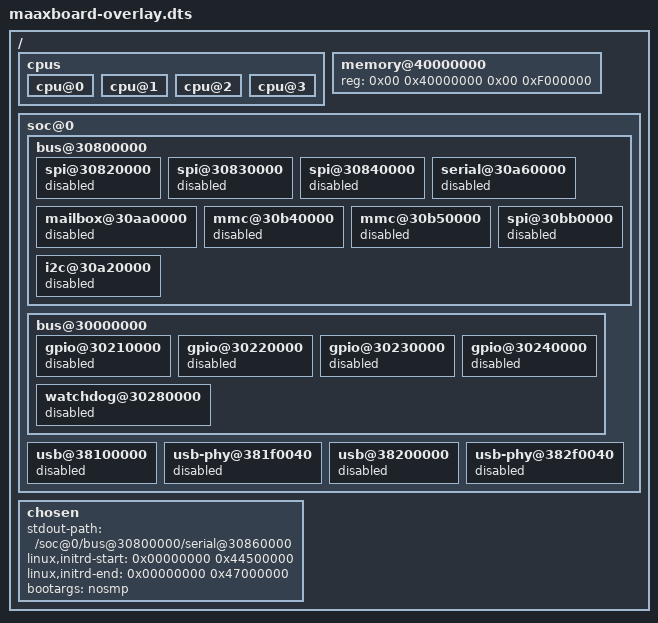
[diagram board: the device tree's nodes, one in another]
/ {

    cpus {

        cpu@0 {
            /delete-property/ cpu-idle-states;
        };

        cpu@1 {
            /delete-property/ cpu-idle-states;
        };

        cpu@2 {
            /delete-property/ cpu-idle-states;
        };

        cpu@3 {
            /delete-property/ cpu-idle-states;
        };

        /delete-node/ idle-states;

    };

    memory@40000000 {
        device_type = "memory";
        reg = <0x00 0x40000000 0x00 0xF000000>;
    };

    /delete-node/ reserved-memory;

    soc@0 {

        bus@30800000 {

            spi@30820000 {
                status = "disabled";
            };

            spi@30830000 {
                status = "disabled";
            };

            spi@30840000 {
                status = "disabled";
            };

            serial@30a60000 {
                status = "disabled";
            };

            mailbox@30aa0000 {
                status = "disabled";
            };

            mmc@30b40000 {
                status = "disabled";
            };

            mmc@30b50000 {
                status = "disabled";
            };

            spi@30bb0000 {
                status = "disabled";
            };

            i2c@30a20000 {
                status = "disabled";
            };
        };

        bus@30000000 {

            gpio@30210000 {
                status = "disabled";
            };

            gpio@30220000 {
                status = "disabled";
            };

            gpio@30230000 {
                status = "disabled";
            };

            gpio@30240000 {
                status = "disabled";
            };

            watchdog@30280000 {
                status = "disabled";
            };

        };

        usb@38100000 {
            status = "disabled";
        };

        usb-phy@381f0040 {
            status = "disabled";
        };

        usb@38200000 {
            status = "disabled";
        };

        usb-phy@382f0040 {
            status = "disabled";
        };

    };

    chosen {
        stdout-path = "/soc@0/bus@30800000/serial@30860000";
        linux,initrd-start = <0x00000000 0x44500000>;
        linux,initrd-end =   <0x00000000 0x47000000>;
        /* nosmp: Ensure single core. */
        bootargs = "nosmp";
    };

};
